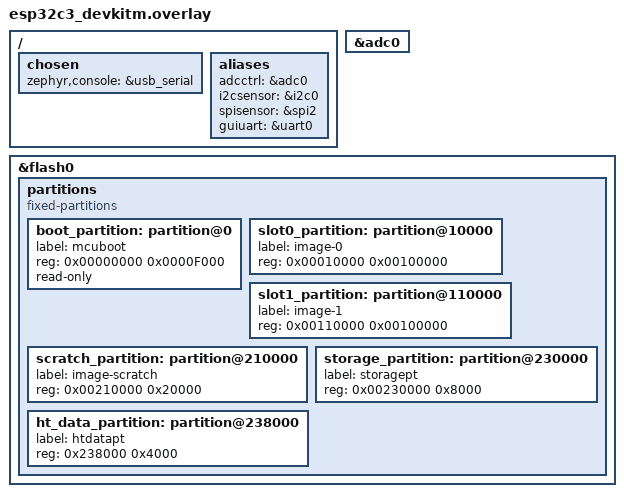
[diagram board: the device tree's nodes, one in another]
/ {
  chosen {
    zephyr,console = &usb_serial;
    /delete-property/ zephyr,shell-uart;
  };

  aliases {
    adcctrl = &adc0;
    i2csensor = &i2c0;
    spisensor = &spi2;
    guiuart = &uart0;
  };
};

&adc0 {
  status = "okay";
};

/delete-node/ &storage_partition;

&flash0 {
	status = "okay";
	partitions {
		compatible = "fixed-partitions";
		#address-cells = <1>;
		#size-cells = <1>;

		/* Reserve 60kB for the bootloader */
		boot_partition: partition@0 {
			label = "mcuboot";
			reg = <0x00000000 0x0000F000>;
			read-only;
		};

		/* Reserve 1024kB for the application in slot 0 */
		slot0_partition: partition@10000 {
			label = "image-0";
			reg = <0x00010000 0x00100000>;
		};

		/* Reserve 1024kB for the application in slot 1 */
		slot1_partition: partition@110000 {
			label = "image-1";
			reg = <0x00110000 0x00100000>;
		};

		/* Reserve 128kB for the scratch partition */
		scratch_partition: partition@210000 {
			label = "image-scratch";
			reg = <0x00210000 0x20000>;
		};

    storage_partition: partition@230000 {
      label = "storagept";
      reg = <0x00230000 0x8000>;
  	};

		ht_data_partition: partition@238000 {
			label = "htdatapt";
			reg = <0x238000 0x4000>;
		};
	};
};
